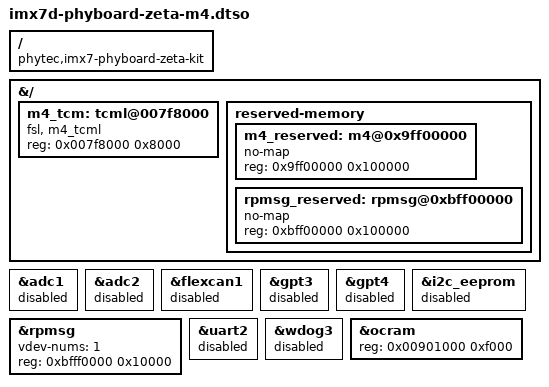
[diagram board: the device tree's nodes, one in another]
// SPDX-License-Identifier: GPL-2.0-or-later
/*
 * Copyright (C) 2019-2023 PHYTEC America, LLC
 *
 * DT overlay for PHYTEC kit KPB-01910-004
 */

/dts-v1/;
/plugin/;

/ {
	compatible = "phytec,imx7-phyboard-zeta-kit",
		     "phytec,imx7-phycore-som",
		     "fsl,imx7d";
};

&{/} {
	m4_tcm: tcml@007f8000 {
		compatible = "fsl, m4_tcml";
		reg = <0x007f8000 0x8000>;
	};

	reserved-memory {
		#address-cells = <1>;
		#size-cells = <1>;
		ranges;

		m4_reserved: m4@0x9ff00000 {
			no-map;
			reg = <0x9ff00000 0x100000>;
		};

		rpmsg_reserved: rpmsg@0xbff00000 {
			no-map;
			reg = <0xbff00000 0x100000>;
		};
	};
};

&adc1 {
	status = "disabled";
};

&adc2 {
	status = "disabled";
};

&flexcan1 {
	status = "disabled";
};

&gpt3 {
	status = "disabled";
};

&gpt4 {
	status = "disabled";
};

&i2c_eeprom {
	status = "disabled";
};

&rpmsg {
	vdev-nums = <1>;
	reg = <0xbfff0000 0x10000>;
	status = "okay";
};

&uart2 {
	status = "disabled";
};

&wdog3 {
	status = "disabled";
};

&ocram {
	reg = <0x00901000 0xf000>;
};
